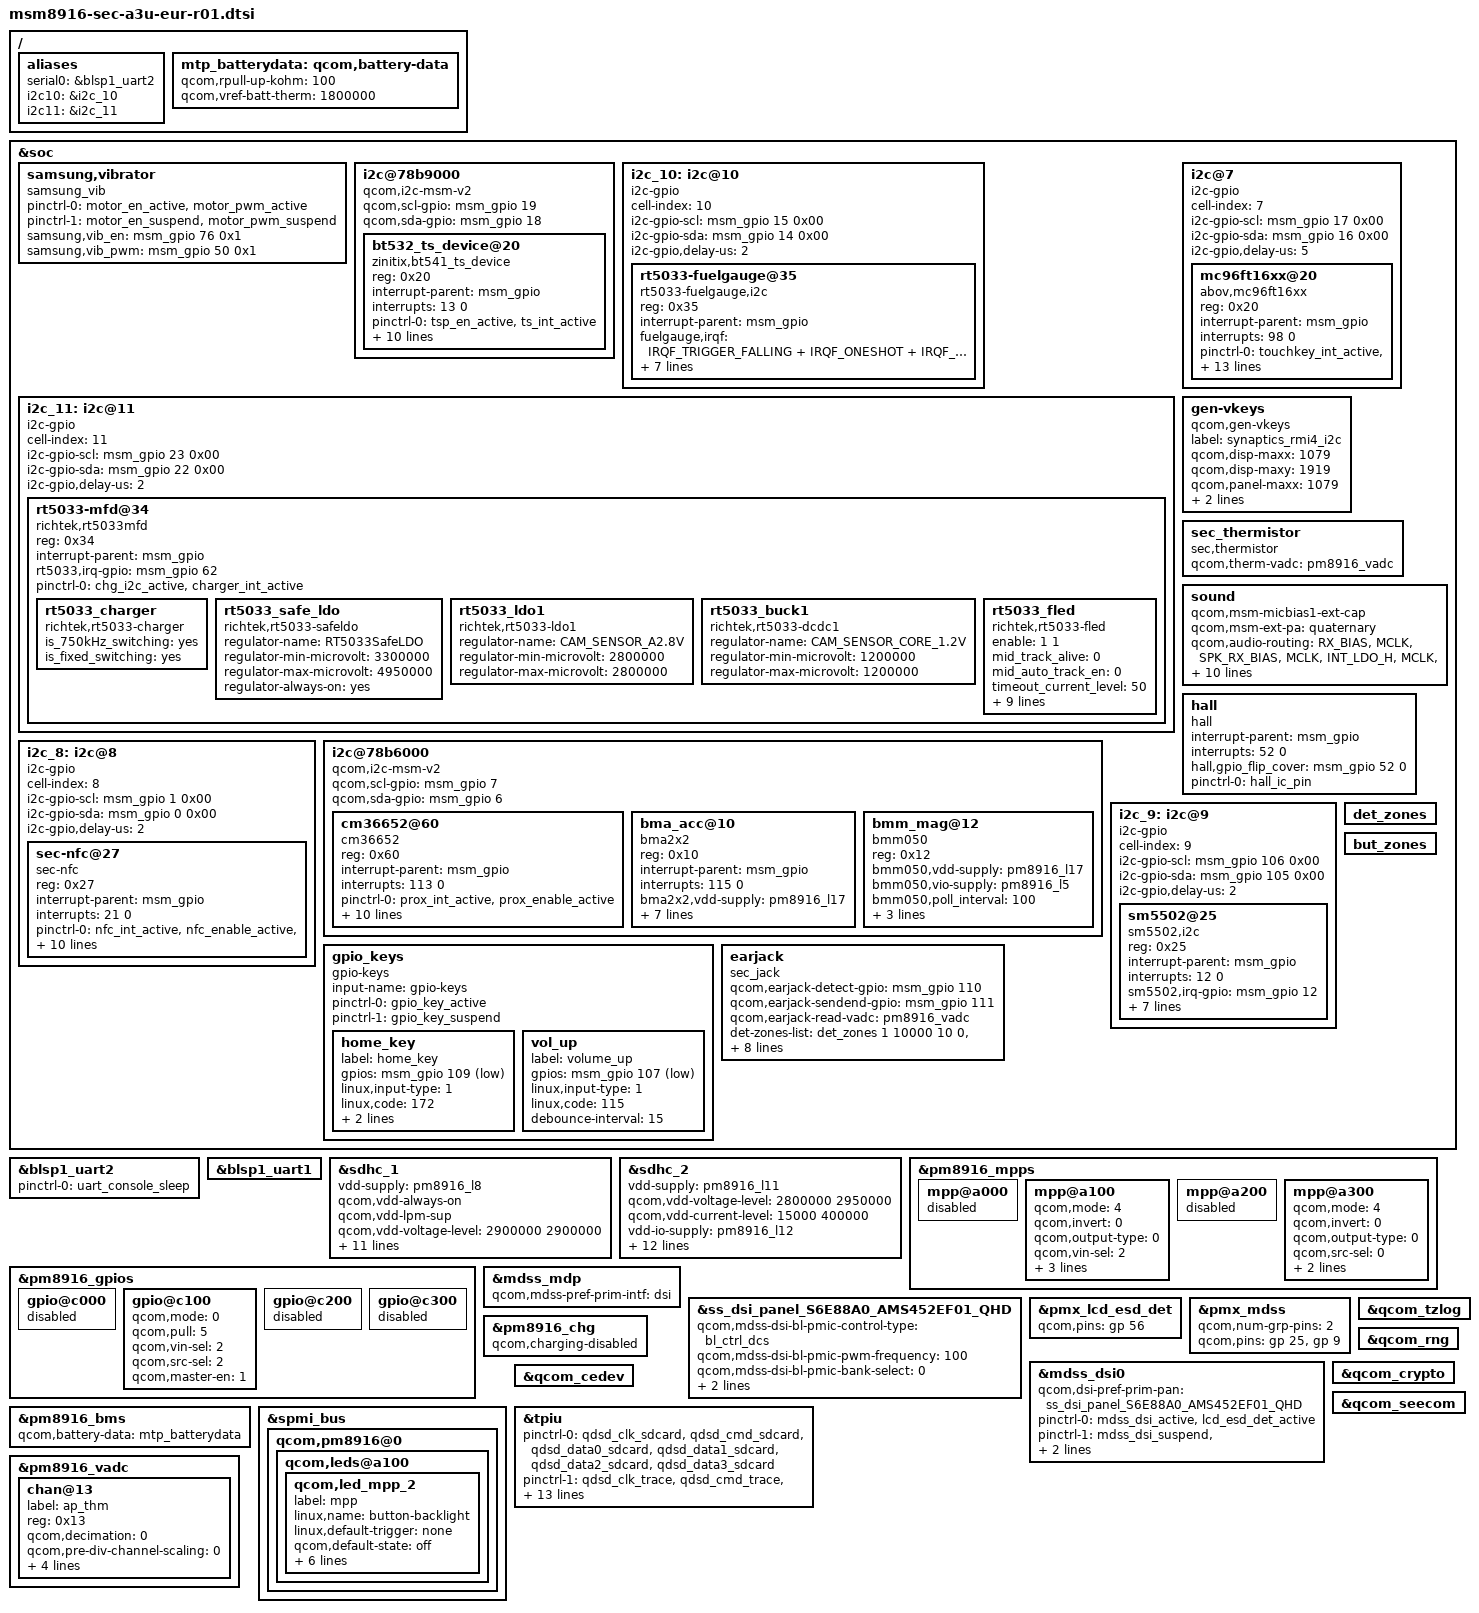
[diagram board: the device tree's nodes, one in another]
/* Copyright (c) 2014, The Linux Foundation. All rights reserved.
 *
 * This program is free software; you can redistribute it and/or modify
 * it under the terms of the GNU General Public License version 2 and
 * only version 2 as published by the Free Software Foundation.
 *
 * This program is distributed in the hope that it will be useful,
 * but WITHOUT ANY WARRANTY; without even the implied warranty of
 * MERCHANTABILITY or FITNESS FOR A PARTICULAR PURPOSE.  See the
 * GNU General Public License for more details.
 */

#include "msm8916.dtsi"
#include "msm8916-pinctrl-sec-a3u-eur-r01.dtsi"
#include "msm8916-camera.dtsi"
#include "msm8916-camera-sensor-cdp.dtsi"
#include "msm8916-sec-a3u-battery-r00.dtsi"
#include "../../../../../../drivers/video/msm/mdss/samsung/S6E88A0_AMS452EF01/dsi_panel_S6E88A0_AMS452EF01_qhd_octa_video.dtsi"

/ {
	aliases {
		serial0 = &blsp1_uart2;

		/*i2c-gpio bus_id*/
		i2c10 = &i2c_10;
		i2c11 = &i2c_11;
	};
};

&soc {
	samsung,vibrator {
		compatible = "samsung_vib";
		pinctrl-names = "tlmm_motor_active","tlmm_motor_suspend";
		pinctrl-0 = <&motor_en_active &motor_pwm_active>;
		pinctrl-1 = <&motor_en_suspend &motor_pwm_suspend>;
		samsung,vib_en = <&msm_gpio 76 0x1>;
		samsung,vib_pwm = <&msm_gpio 50 0x1>;
		status = "ok";
	};

	i2c@78b9000 { /* BLSP1 QUP5 */
		status = "ok";
		compatible = "qcom,i2c-msm-v2";
		qcom,scl-gpio = <&msm_gpio 19 0>;
		qcom,sda-gpio = <&msm_gpio 18 0>;

		bt532_ts_device@20 {
			compatible = "zinitix,bt541_ts_device";
			reg = <0x20>;
			interrupt-parent = <&msm_gpio>;
			interrupts = <13 0>;
			pinctrl-names = "tsp_en_gpio_active", "tsp_en_gpio_suspend";
			pinctrl-0 = <&tsp_en_active &ts_int_active>;
			pinctrl-1 = <&tsp_en_suspend &ts_int_suspend>;
			vddo-supply = <&pm8916_l6>;
			zinitix,vdd_en-gpio = <&msm_gpio 73 0x01>;
			zinitix,irq-gpio = <&msm_gpio 13 0x00>;
			zinitix,x_resolution = <540>;
			zinitix,y_resolution = <960>;
			zinitix,page_size = <128>;
			zinitix,orientation = <0>;
			zinitix,tsp_vdd_supply_type = <0>;
			zinitix,pname = "SM-A3000";
		};
	};

       i2c_10:i2c@10 {
		cell-index = <10>;
		compatible = "i2c-gpio";
		i2c-gpio-scl = <&msm_gpio 15 0x00>;
		i2c-gpio-sda = <&msm_gpio 14 0x00>;
		i2c-gpio,delay-us = <2>;
		#address-cells = <1>;
		#size-cells = <0>;

		rt5033-fuelgauge@35{
			compatible = "rt5033-fuelgauge,i2c";
			reg = <0x35>;
			interrupt-parent = <&msm_gpio>;
			fuelgauge,irqf = "IRQF_TRIGGER_FALLING + IRQF_ONESHOT + IRQF_NO_SUSPEND";
			fuelgauge,fuel_int = <&msm_gpio 121 0x1>;
			pinctrl-names = "default";
			pinctrl-0 = <&fg_i2c_active &fuel_int_active>;

			fuelgauge,capacity_max = <1000>;
			fuelgauge,capacity_max_margin = <50>;
			fuelgauge,capacity_min = <0>;
			fuelgauge,capacity_calculation_type = <0x17>;
			fuelgauge,fuel_alert_soc = <1>;
		};
	};

       i2c_11:i2c@11 {
		cell-index = <11>;
		compatible = "i2c-gpio";
		i2c-gpio-scl = <&msm_gpio 23 0x00>;
		i2c-gpio-sda = <&msm_gpio 22 0x00>;
		i2c-gpio,delay-us = <2>;
		#address-cells = <1>;
		#size-cells = <0>;

		rt5033-mfd@34{
			compatible = "richtek,rt5033mfd";
			reg = <0x34>;
			interrupt-parent = <&msm_gpio>;
			rt5033,irq-gpio = <&msm_gpio 62 0x00>;
			pinctrl-names = "default";
			pinctrl-0 = <&chg_i2c_active &charger_int_active>;

			rt5033_charger {
				compatible = "richtek,rt5033-charger";
				is_750kHz_switching = "yes";
				is_fixed_switching = "yes";
			};

			rt5033_safe_ldo {
				compatible = "richtek,rt5033-safeldo";
				regulator-name = "RT5033SafeLDO"; /* constraints->name, change name by yourself*/
				regulator-min-microvolt = <3300000>;
				regulator-max-microvolt = <4950000>; /* if max == min then apply_uV = 1 */
				/* regulator-microvolt-offset = <0>; optional*/
				/* regulator-boot-on = "yes"; optional, exist = enabled */
				regulator-always-on = "yes";
				/* regulator-ramp-delay = <100>; optional*/
			};

			rt5033_ldo1 {
				compatible = "richtek,rt5033-ldo1";
				regulator-name = "CAM_SENSOR_A2.8V"; /* change name by yourself */
				regulator-min-microvolt = <2800000>;
				regulator-max-microvolt = <2800000>; /* max == min then apply_uV = 1 */
				/* regulator-microvolt-offset = < >; optional*/
				/* regulator-boot-on = "yes"; optional, exist = enabled */
				/* regulator-always-on = "yes"; optional, exist = enabled */
				/* regulator-ramp-delay = <100>; optional*/
			};


			rt5033_buck1 {
				compatible = "richtek,rt5033-dcdc1";
				regulator-name = "CAM_SENSOR_CORE_1.2V"; /* change name by yourself */
				regulator-min-microvolt = <1200000>;
				regulator-max-microvolt = <1200000>; /* max == min then apply_uV = 1 */
				/* regulator-microvolt-offset = < >; optional*/
				/* regulator-boot-on = "yes"; optional, exist = enabled */
				/* regulator-always-on = "yes"; optional, exist = enabled */
				/* regulator-ramp-delay = <100>; optional*/
			};

			rt5033_fled {
				compatible = "richtek,rt5033-fled";
				enable = <1 1>;
				mid_track_alive = <0>;
				mid_auto_track_en = <0>;
				timeout_current_level = <50>;
				strobe_current = <500>;
				strobe_timeout = <544>;
				torch_current = <63>;
				lv_protection = <3000>;
				mid_level = <4400>;
				rt5033,led1-gpio = <&msm_gpio 34 0x00>;
				rt5033,led2-gpio = <&msm_gpio 36 0x00>;
				pinctrl-names = "fled_default","fled_sleep";
				pinctrl-0 = <&cam_flash_active>;
				pinctrl-1 = <&cam_flash_sleep>;
			};
		};
	};

	i2c@7 {
		cell-index = <7>;
		compatible = "i2c-gpio";
		i2c-gpio-scl = <&msm_gpio 17 0x00>;
		i2c-gpio-sda = <&msm_gpio 16 0x00>;
		i2c-gpio,delay-us = <5>;
		#address-cells = <1>;
		#size-cells = <0>;
		mc96ft16xx@20{
			compatible = "abov,mc96ft16xx";
			reg = <0x20>;
			interrupt-parent = <&msm_gpio>;
			interrupts = <98 0>;
			pinctrl-names = "touchkey_active", "touchkey_suspend";
			pinctrl-0 = <&touchkey_int_active &touchkey_en_active &touchkey_i2c_sda_active &touchkey_i2c_scl_active>;
			pinctrl-1 = <&touchkey_int_suspend &touchkey_en_suspend &touchkey_i2c_sda_suspend &touchkey_i2c_scl_suspend>;
			abov,sda-gpio = <&msm_gpio 16 0>;
			abov,scl-gpio = <&msm_gpio 17 0>;
			abov,irq-gpio = <&msm_gpio 98 0>;
			abov,tkey_en-gpio = <&msm_gpio 86 0>;
			abov,tkey_led_en-gpio = <&msm_gpio 60 0>;
			vddo-supply = <&pm8916_l6>;
			abov,gpio_seperated = <1>;
		};
	};

	gen-vkeys {
		compatible = "qcom,gen-vkeys";
		label = "synaptics_rmi4_i2c";
		qcom,disp-maxx = <1079>;
		qcom,disp-maxy = <1919>;
		qcom,panel-maxx = <1079>;
		qcom,panel-maxy = <2084>;
		qcom,key-codes = <158 139 172 217>;
	};

	sec_thermistor {
		compatible = "sec,thermistor";
		qcom,therm-vadc = <&pm8916_vadc>;
	};

	i2c_8: i2c@8 {
		cell-index = <8>;
		compatible = "i2c-gpio";
		i2c-gpio-scl = <&msm_gpio 1 0x00>;
		i2c-gpio-sda = <&msm_gpio 0 0x00>;
		i2c-gpio,delay-us = <2>;
		#address-cells = <1>;
		#size-cells = <0>;
		sec-nfc@27 {
			compatible = "sec-nfc";
			reg = <0x27>;
			interrupt-parent = <&msm_gpio>;
			interrupts = <21 0>;
			pinctrl-names = "nfc_active","nfc_suspend";
			pinctrl-0 = <&nfc_int_active &nfc_enable_active &nfc_firmware_active &nfc_i2c_active>;
			pinctrl-1 = <&nfc_int_suspend &nfc_enable_suspend &nfc_firmware_suspend &nfc_i2c_suspend>;
			vdd_nfc-supply = <&pm8916_l6>;
			sec-nfc,firm-gpio = <&msm_gpio 49 0x01>;
			sec-nfc,ven-gpio = <&msm_gpio 20 0x01>;
			sec-nfc,irq-gpio = <&msm_gpio 21 0x00>;
			clocks = <&clock_rpm clk_bb_clk2_pin>;
			clock-names = "nfc_clock";
			nfc_ldo-supply = <&pm8916_l14>;
		};
	};

	i2c@78b6000 { /* BLSP1 QUP2 */
		compatible = "qcom,i2c-msm-v2";
		qcom,scl-gpio = <&msm_gpio 7 0>;
		qcom,sda-gpio = <&msm_gpio 6 0>;
		cm36652@60 {
			compatible = "cm36652";
			reg = <0x60>;
			interrupt-parent = <&msm_gpio>;
			interrupts = <113 0>;
			pinctrl-names = "prox_active","prox_suspend";
			pinctrl-0 = <&prox_int_active &prox_enable_active>;
			pinctrl-1 = <&prox_int_suspend &prox_enable_suspend>;
			cm36652,leden_gpio = <&msm_gpio 8 0x1>;
			cm36652,irq_gpio = <&msm_gpio 113 0x1>;
			cm36652,vdd-supply = <&pm8916_l17>;
			cm36652,vio-supply = <&pm8916_l5>;
			cm36652,default_hi_thd = <20>;
			cm36652,default_low_thd = <17>;
			cm36652,cancel_hi_thd = <10>;
			cm36652,cancel_low_thd = <7>;
		};		bma_acc@10 {
			compatible = "bma2x2";
			reg = <0x10>;
			interrupt-parent = <&msm_gpio>;
			interrupts = <115 0>;
			bma2x2,vdd-supply = <&pm8916_l17>;
			bma2x2,vio-supply = <&pm8916_l5>;
			bma2x2,gpio_int1 = <&msm_gpio 115 0x00>;
			bma2x2,fs_range = <0x00>;
			bma2x2,poll_interval = <100>;
			bma2x2,min_interval = <2>;
			bma2x2,supply_type = <1>;
			bma2x2,accel_place = <5>;
		};
		bmm_mag@12 {
			compatible = "bmm050";
			reg = <0x12>;
			bmm050,vdd-supply = <&pm8916_l17>;
			bmm050,vio-supply = <&pm8916_l5>;
			bmm050,poll_interval = <100>;
			bmm050,min_interval = <13>;
			bmm050,fs_range = <0x60>;
			bmm050,magnetic_place = <5>;
		};

	};

	/* Over-riding model specific changes */
	sound {
		qcom,msm-micbias1-ext-cap;
		qcom,msm-ext-pa = "quaternary";
		qcom,audio-routing =
			"RX_BIAS", "MCLK",
			"SPK_RX_BIAS", "MCLK",
			"INT_LDO_H", "MCLK",
			"MIC BIAS External", "Handset Mic",
			"MIC BIAS External", "Secondary Mic",
			"AMIC1", "MIC BIAS External",
			"AMIC2", "Headset Mic",
			"AMIC3", "MIC BIAS External";
		pinctrl-names = "cdc_lines_act",
				"cdc_lines_sus",
				"cdc_lines_quat_ext_act",
				"cdc_lines_quat_ext_sus";
		pinctrl-0 = <&cdc_pdm_lines_act>;
		pinctrl-1 = <&cdc_pdm_lines_sus>;
		pinctrl-2 = <&cdc_pdm_lines_act &ext_cdc_tlmm_lines_act>;
		pinctrl-3 = <&cdc_pdm_lines_sus &ext_cdc_tlmm_lines_sus>;
	};
};

&blsp1_uart2 {
	status = "ok";
	pinctrl-names = "default";
	pinctrl-0 = <&uart_console_sleep>;
};

&soc {
	gpio_keys {
		compatible = "gpio-keys";
		input-name = "gpio-keys";
		pinctrl-names = "tlmm_gpio_key_active","tlmm_gpio_key_suspend";
		pinctrl-0 = <&gpio_key_active>;
		pinctrl-1 = <&gpio_key_suspend>;

		home_key {
			label = "home_key";
			gpios = <&msm_gpio 109 0x1>;
			linux,input-type = <1>;
			linux,code = <172>;
			gpio-key,wakeup;
			debounce-interval = <15>;
		};

		vol_up {
			label = "volume_up";
			gpios = <&msm_gpio 107 0x1>;
			linux,input-type = <1>;
			linux,code = <115>;
			debounce-interval = <15>;
		};
	};

	hall {
		status = "okay";
		compatible = "hall";
		interrupt-parent = <&msm_gpio>;
		interrupts = <52 0>;
		hall,gpio_flip_cover = <&msm_gpio 52 0>;
		pinctrl-names = "pmx_hall_ic_pin";
		pinctrl-0 = <&hall_ic_pin>;

	};

	i2c_9:i2c@9 { /*SM5502 GPIO-I2C*/
		cell-index = <9>;
		compatible = "i2c-gpio";
		i2c-gpio-scl = <&msm_gpio 106 0x00>;
		i2c-gpio-sda = <&msm_gpio 105 0x00>;
		i2c-gpio,delay-us = <2>;
		#address-cells = <1>;
		#size-cells = <0>;

		sm5502@25{
			compatible = "sm5502,i2c";
			reg = <0x25>;
			interrupt-parent = <&msm_gpio>;
			interrupts= <12 0>;
			sm5502,irq-gpio = <&msm_gpio 12 0x00>;
			sm5502,gpio-sda = <&msm_gpio 105 0x00>;
			sm5502,gpio-scl = <&msm_gpio 106 0x00>;
			sm5502,uarton-gpio = <&msm_gpio 114 0x00>;
			pinctrl-names = "sm5502_i2c_active","sm5502_i2c_suspend";
			pinctrl-0 = <&muic_i2c_active &muic_int_pin &muic_chg_det>;
			pinctrl-1 = <&muic_i2c_suspend &muic_int_pin &muic_chg_det>;
		};
	};

	det_zones: det_zones {
		#list-det-cells = <4>;
	};

	but_zones: but_zones {
		#list-but-cells = <3>;
	};

	earjack {
		compatible = "sec_jack";
		qcom,earjack-detect-gpio = <&msm_gpio 110 0x0>;
		qcom,earjack-sendend-gpio = <&msm_gpio 111 0x0>;
		qcom,earjack-read-vadc = <&pm8916_vadc>;

		det-zones-list = <&det_zones 1 10000 10 0>,
				 <&det_zones 972 10000 10 0>,
				 <&det_zones 1901 10000 10 1>,
				 <&det_zones 2800 10000 10 1>;
		but-zones-list = <&but_zones 0 1 317>,
				 <&but_zones 1 318 447>,
				 <&but_zones 2 448 1200>;
		mpp-channel-scaling = <2 1 1>;
		pinctrl-names = "earjack_gpio_active","earjack_gpio_suspend";
		pinctrl-0 = <&earjack_det_act &earjack_switch_act>;
		pinctrl-1 = <&earjack_det_sus &earjack_switch_sus>;
	};

};

&blsp1_uart1 {
	status = "ok";
};

&sdhc_1 {
	vdd-supply = <&pm8916_l8>;
	qcom,vdd-always-on;
	qcom,vdd-lpm-sup;
	qcom,vdd-voltage-level = <2900000 2900000>;
	qcom,vdd-current-level = <200 400000>;

	vdd-io-supply = <&pm8916_l5>;
	qcom,vdd-io-always-on;
	qcom,vdd-io-lpm-sup;
	qcom,vdd-io-voltage-level = <1800000 1800000>;
	qcom,vdd-io-current-level = <200 60000>;

	pinctrl-names = "active", "sleep";
	pinctrl-0 = <&sdc1_clk_on &sdc1_cmd_on &sdc1_data_on>;
	pinctrl-1 = <&sdc1_clk_off &sdc1_cmd_off &sdc1_data_off>;

	qcom,nonremovable;

	status = "ok";
};

&sdhc_2 {
	vdd-supply = <&pm8916_l11>;
	qcom,vdd-voltage-level = <2800000 2950000>;
	qcom,vdd-current-level = <15000 400000>;

	vdd-io-supply = <&pm8916_l12>;
	qcom,vdd-io-voltage-level = <1800000 2950000>;
	qcom,vdd-io-current-level = <200 50000>;

	pinctrl-names = "active", "sleep";
	pinctrl-0 = <&sdc2_clk_on &sdc2_cmd_on &sdc2_data_on &sdc2_cd_on>;
	pinctrl-1 = <&sdc2_clk_off &sdc2_cmd_off &sdc2_data_off &sdc2_cd_off>;

	#address-cells = <0>;
	interrupt-parent = <&sdhc_2>;
	interrupts = <0 1 2>;
	#interrupt-cells = <1>;
	interrupt-map-mask = <0xffffffff>;
	interrupt-map = <0 &intc 0 125 0
			1 &intc 0 221 0
			2 &msm_gpio 38 0>;
	interrupt-names = "hc_irq", "pwr_irq", "status_irq";
	cd-gpios = <&msm_gpio 38 0x1>;

	status = "ok";
};

&pm8916_mpps {
	mpp@a000 { /* MPP 1 */
		/* VDD_PX */
		status = "disabled";
	};

	mpp@a100 { /* MPP 2 */
		status = "ok";
		qcom,mode = <4>; // AIN input
		qcom,invert = <0>; //No Invert
		qcom,output-type = <0>; //CMOS
		qcom,vin-sel = <2>; //PM8971_S3 1.8v
		qcom,src-sel = <0>; //MPP Constant
		qcom,ain-route = <1>; // QPNP_PIN_AIN_AMUX_CH6 = 1 for MPP2
		qcom,master-en = <1>; // Function constant
	};

	mpp@a200 { /* MPP 3 */
		/* VREF DAC */
		status = "disabled";
	};

	mpp@a300 { /* MPP 4 */
		status = "ok";
		qcom,mode = <4>; // AIN input
		qcom,invert = <0>; //No Invert
		qcom,output-type = <0>; //CMOS
		qcom,src-sel = <0>; //MPP Constant
		qcom,ain-route = <3>; // QPNP_PIN_AIN_AMUX_CH8 = 3 for MPP4
		qcom,master-en = <1>; // Function constant
	};

};

&pm8916_gpios {
	gpio@c000 { /* GPIO 1 */
		/* Battery UICC Alarm */
		status = "disabled";
	};

	gpio@c100 { /* GPIO 2 */
		/* NFC_CLK_REQ */
		qcom,mode = <0>; /* QPNP_PIN_MODE_DIG_IN */
		qcom,pull = <5>; /* QPNP_PIN_PULL_NO */
		qcom,vin-sel = <2>; /* QPNP_PIN_VIN2 */
		qcom,src-sel = <2>; /* QPNP_PIN_SEL_FUNC_1 */
		qcom,master-en = <1>;
	};

	gpio@c200 { /* GPIO 3 */
		/* External regulator control for WTR */
		status = "disabled";
	};

	gpio@c300 { /* GPIO 4 */
		/* External regulator control for APC */
		status = "disabled";
	};
};

&mdss_mdp {
	qcom,mdss-pref-prim-intf = "dsi";
};

&ss_dsi_panel_S6E88A0_AMS452EF01_QHD {
	qcom,mdss-dsi-bl-pmic-control-type = "bl_ctrl_dcs";
	qcom,mdss-dsi-bl-pmic-pwm-frequency = <100>;
	qcom,mdss-dsi-bl-pmic-bank-select = <0>;
	samsung,panel-extra-power-gpio1 = <&msm_gpio 9 0>;
	qcom,cont-splash-enabled;
};

&pmx_lcd_esd_det {
	qcom,pins = <&gp 56>;
};

&pmx_mdss {
                 qcom,num-grp-pins = <2>;
                 qcom,pins =  <&gp 25>, <&gp 9>;
};
&mdss_dsi0 {
	qcom,dsi-pref-prim-pan = <&ss_dsi_panel_S6E88A0_AMS452EF01_QHD>;
	pinctrl-names = "mdss_default", "mdss_sleep";
	pinctrl-0 = <&mdss_dsi_active &lcd_esd_det_active>;
	pinctrl-1 = <&mdss_dsi_suspend &lcd_esd_det_suspend>;
	qcom,platform-reset-gpio = <&msm_gpio 25 0>;
};

&pm8916_chg {
	status = "ok";
	qcom,charging-disabled;
};

/ {
	mtp_batterydata: qcom,battery-data {
		qcom,rpull-up-kohm = <100>;
		qcom,vref-batt-therm = <1800000>;

		#include "batterydata-palladium.dtsi"
	};
};

&pm8916_bms {
	status = "ok";
	qcom,battery-data = <&mtp_batterydata>;
};

&spmi_bus {
	qcom,pm8916@0 {
		qcom,leds@a100 {
			status = "okay";
			qcom,led_mpp_2 {
				label = "mpp";
				linux,name = "button-backlight";
				linux,default-trigger = "none";
				qcom,default-state = "off";
				qcom,max-current = <40>;
				qcom,current-setting = <5>;
				qcom,id = <6>;
				qcom,mode = "manual";
				qcom,source-sel = <1>;
				qcom,mode-ctrl = <0x60>;
			};
		};
	};
};

&qcom_tzlog {
	status = "okay";
};

&qcom_rng {
	status = "okay";
};

&qcom_crypto {
	status = "okay";
};

&qcom_cedev {
	status = "okay";
};

&qcom_seecom {
	status = "okay";
};

/* CoreSight */
&tpiu {
      pinctrl-names = "sdcard", "trace", "swduart",
		      "swdtrc", "jtag", "spmi";
       /* NIDnT */
      pinctrl-0 = <&qdsd_clk_sdcard &qdsd_cmd_sdcard
                  &qdsd_data0_sdcard &qdsd_data1_sdcard
                  &qdsd_data2_sdcard &qdsd_data3_sdcard>;
      pinctrl-1 = <&qdsd_clk_trace &qdsd_cmd_trace
                  &qdsd_data0_trace &qdsd_data1_trace
                  &qdsd_data2_trace &qdsd_data3_trace>;
      pinctrl-2 = <&qdsd_cmd_swduart &qdsd_data0_swduart
                  &qdsd_data1_swduart &qdsd_data2_swduart
                  &qdsd_data3_swduart>;
      pinctrl-3 = <&qdsd_clk_swdtrc &qdsd_cmd_swdtrc
                  &qdsd_data0_swdtrc &qdsd_data1_swdtrc
                  &qdsd_data2_swdtrc &qdsd_data3_swdtrc>;
      pinctrl-4 = <&qdsd_cmd_jtag &qdsd_data0_jtag
                  &qdsd_data1_jtag &qdsd_data2_jtag
                  &qdsd_data3_jtag>;
      pinctrl-5 = <&qdsd_clk_spmi &qdsd_cmd_spmi
                  &qdsd_data0_spmi &qdsd_data3_spmi>;
};
&pm8916_vadc {
	chan@13 {
		label = "ap_thm";
		reg = <0x13>; // channel 19 for MPP4 , 1:1scale
		qcom,decimation = <0>;
		qcom,pre-div-channel-scaling = <0>; // 1:1scale
		qcom,calibration-type = "ratiometric";
		qcom,scale-function = <1>;
		qcom,hw-settle-time = <2>;
		qcom,fast-avg-setup = <0>;
	};
};
